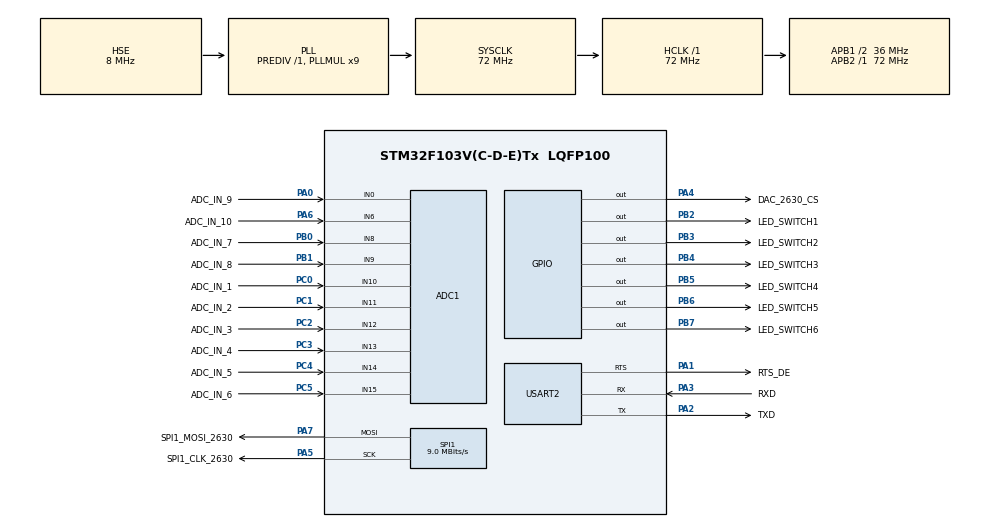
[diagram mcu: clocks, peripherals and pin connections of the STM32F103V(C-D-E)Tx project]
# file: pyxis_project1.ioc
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Mcu.Family=STM32F1
SPI1.VirtualType=VM_MASTER
ADC1.ContinuousConvMode=DISABLE
VP_TIM4_VS_OPM.Mode=OPM_bit
ADC1.SamplingTime-6\#ChannelRegularConversion=ADC_SAMPLETIME_71CYCLES_5
PC0.GPIO_Label=ADC_IN_1
PA6.GPIO_Label=ADC_IN_10
PB0.GPIO_Label=ADC_IN_7
PB6.GPIO_Label=LED_SWITCH5
ADC1.SamplingTime-12\#ChannelRegularConversion=ADC_SAMPLETIME_71CYCLES_5
ADC1.Channel-8\#ChannelRegularConversion=ADC_CHANNEL_15
RCC.SYSCLKSource=RCC_SYSCLKSOURCE_PLLCLK
ProjectManager.StackSize=0x400
ADC1.Channel-5\#ChannelRegularConversion=ADC_CHANNEL_12
ADC1.Rank-11\#ChannelRegularConversion=9
ADC1.Channel-3\#ChannelRegularConversion=ADC_CHANNEL_10
SPI1.Direction=SPI_DIRECTION_2LINES
RCC.HCLKFreq_Value=72000000
RCC.APB2TimFreq_Value=72000000
PB6.Signal=GPIO_Output
SPI1.CalculateBaudRate=9.0 MBits/s
PC3.Signal=ADCx_IN13
OSC_OUT.Mode=HSE-External-Oscillator
OSC_OUT.Signal=RCC_OSC_OUT
RCC.AHBFreq_Value=72000000
PB2.Signal=GPIO_Output
SH.ADCx_IN15.0=ADC1_IN15,IN15
RCC.PLLMUL=RCC_PLL_MUL9
ADC1.SamplingTime-4\#ChannelRegularConversion=ADC_SAMPLETIME_71CYCLES_5
ADC1.Channel-6\#ChannelRegularConversion=ADC_CHANNEL_13
PC14-OSC32_IN.Mode=LSE-External-Oscillator
PC4.GPIO_Label=ADC_IN_5
PA14.Mode=Serial_Wire
PB1.GPIO_Label=ADC_IN_8
SH.ADCx_IN8.0=ADC1_IN8,IN8
PB7.Signal=GPIO_Output
SH.ADCx_IN0.0=ADC1_IN0,IN0
TIM4.Period=49
PB7.GPIO_Label=LED_SWITCH6
Mcu.Package=LQFP100
ADC1.SamplingTime-11\#ChannelRegularConversion=ADC_SAMPLETIME_71CYCLES_5
PB1.Signal=ADCx_IN9
PA6.Signal=ADCx_IN6
SH.ADCx_IN14.0=ADC1_IN14,IN14
USART2.VirtualMode=VM_ASYNC
PA2.GPIO_Label=TXD
ADC1.Channel-11\#ChannelRegularConversion=ADC_CHANNEL_0
SH.ADCx_IN9.0=ADC1_IN9,IN9
PB5.GPIO_Label=LED_SWITCH4
RCC.APB1TimFreq_Value=72000000
PC5.Signal=ADCx_IN15
ADC1.Rank-6\#ChannelRegularConversion=4
SPI1.BaudRatePrescaler=SPI_BAUDRATEPRESCALER_8
ADC1.SamplingTime-8\#ChannelRegularConversion=ADC_SAMPLETIME_71CYCLES_5
PA4.GPIO_Label=DAC_2630_CS
PC2.GPIO_Label=ADC_IN_3
ADC1.Rank-4\#ChannelRegularConversion=2
PB4.Signal=GPIO_Output
PA3.Signal=USART2_RX
PA5.Mode=TX_Only_Simplex_Unidirect_Master
PB3.GPIO_Label=LED_SWITCH2
ADC1.Channel-10\#ChannelRegularConversion=ADC_CHANNEL_9
RCC.PLLSourceVirtual=RCC_PLLSOURCE_HSE
PC15-OSC32_OUT.Mode=LSE-External-Oscillator
SH.ADCx_IN13.0=ADC1_IN13,IN13
PA7.Mode=TX_Only_Simplex_Unidirect_Master
ADC1.Channel-4\#ChannelRegularConversion=ADC_CHANNEL_11
ADC1.Rank-10\#ChannelRegularConversion=8
SH.ADCx_IN6.0=ADC1_IN6,IN6
ADC1.Rank-8\#ChannelRegularConversion=6
PC2.Signal=ADCx_IN12
PC4.Signal=ADCx_IN14
ADC1.DiscontinuousConvMode=ENABLE
PC0.Signal=ADCx_IN10
RCC.APB1CLKDivider=RCC_HCLK_DIV2
PC14-OSC32_IN.Signal=RCC_OSC32_IN
NVIC.USART2_IRQn=true\:1\:0\:true\:false\:false\:true\:false
PA0-WKUP.GPIO_Label=ADC_IN_9
PA0-WKUP.Signal=ADCx_IN0
ADC1.Channel-7\#ChannelRegularConversion=ADC_CHANNEL_14
RCC.ADCPresc=RCC_ADCPCLK2_DIV6
PA3.Mode=Asynchronous
PA13.Signal=SYS_JTMS-SWDIO
SH.ADCx_IN12.0=ADC1_IN12,IN12
ProjectManager.TargetToolchain=MDK-ARM V5
OSC_IN.Signal=RCC_OSC_IN
RCC.USBFreq_Value=72000000
TIM4.Prescaler=7199
PC15-OSC32_OUT.Signal=RCC_OSC32_OUT
PA1.Signal=USART2_RTS
PA5.Signal=SPI1_SCK
board=custom
ADC1.Rank-12\#ChannelRegularConversion=10
ADC1.EnableAnalogWatchDog=false
ADC1.Channel-12\#ChannelRegularConversion=ADC_CHANNEL_6
RCC.APB2Freq_Value=72000000
PA1.Mode=RTS_Only
SH.ADCx_IN11.0=ADC1_IN11,IN11
PB4.GPIO_Label=LED_SWITCH3
SPI1.Mode=SPI_MODE_MASTER
PC1.GPIO_Label=ADC_IN_2
PA1.GPIO_Label=RTS_DE
ADC1.SamplingTime-10\#ChannelRegularConversion=ADC_SAMPLETIME_71CYCLES_5
ADC1.Rank-9\#ChannelRegularConversion=7
ADC1.NbrOfConversion=10
PA13.Mode=Serial_Wire
Mcu.Name=STM32F103V(C-D-E)Tx
PA2.Signal=USART2_TX
ADC1.Channel-9\#ChannelRegularConversion=ADC_CHANNEL_8
PB3.Signal=GPIO_Output
PA4.Signal=GPIO_Output
RCC.SYSCLKFreq_VALUE=72000000
PB5.Signal=GPIO_Output
PA7.GPIO_Label=SPI1_MOSI_2630
ADC1.master=1
PA5.GPIO_Label=SPI1_CLK_2630
ADC1.Rank-3\#ChannelRegularConversion=1
ADC1.SamplingTime-3\#ChannelRegularConversion=ADC_SAMPLETIME_71CYCLES_5
OSC_IN.Mode=HSE-External-Oscillator
PC5.GPIO_Label=ADC_IN_6
PA14.Signal=SYS_JTCK-SWCLK
SH.ADCx_IN10.0=ADC1_IN10,IN10
PB2.GPIO_Label=LED_SWITCH1
ProjectManager.HeapSize=0x200
ADC1.SamplingTime-5\#ChannelRegularConversion=ADC_SAMPLETIME_71CYCLES_5
ADC1.Rank-7\#ChannelRegularConversion=5
NVIC.PriorityGroup=NVIC_PRIORITYGROUP_4
ADC1.NbrOfConversionFlag=1
PA2.Mode=Asynchronous
PC3.GPIO_Label=ADC_IN_4
ADC1.SamplingTime-9\#ChannelRegularConversion=ADC_SAMPLETIME_71CYCLES_5
ADC1.SamplingTime-7\#ChannelRegularConversion=ADC_SAMPLETIME_71CYCLES_5
NVIC.TIM4_IRQn=true\:2\:0\:true\:false\:false\:true\:false
RCC.APB1Freq_Value=36000000
PB0.Signal=ADCx_IN8
ADC1.Rank-5\#ChannelRegularConversion=3
PC1.Signal=ADCx_IN11
PA3.GPIO_Label=RXD
PA7.Signal=SPI1_MOSI

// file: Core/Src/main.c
/* USER CODE BEGIN Header */
/**
  ******************************************************************************
  * @file           : main.c
  * @brief          : Main program body
  ******************************************************************************
  * @attention
  *
  * <h2><center>&copy; Copyright (c) 2020 STMicroelectronics.
  * All rights reserved.</center></h2>
  *
  * This software component is licensed by ST under BSD 3-Clause license,
  * the "License"; You may not use this file except in compliance with the
  * License. You may obtain a copy of the License at:
  *                        opensource.org/licenses/BSD-3-Clause
  *
  ******************************************************************************
  */
/* USER CODE END Header */

#include "main.h"
#include "adc.h"
#include "spi.h"
#include "tim.h"
#include "usart.h"
#include "gpio.h"

void SystemClock_Config(void);

/* USER CODE BEGIN 0 */
void vDelay(uint32_t ulTim)
{
	do
	{
		__NOP();
	}while(--ulTim);
}
/* USER CODE END 0 */

int main(void)
{
  /* USER CODE BEGIN 1 */
	uint8_t i;
	float avg_value[10];
  /* USER CODE END 1 */

  /* MCU Configuration--------------------------------------------------------*/

  /* Reset of all peripherals, Initializes the Flash interface and the Systick. */
  HAL_Init();

  /* USER CODE BEGIN Init */
	LTC2630ISC6_init();
	HAL_ADC_MspInit(&hadc1);
  /* USER CODE END Init */

  /* Configure the system clock */
  SystemClock_Config();

  /* Initialize all configured peripherals */
  MX_GPIO_Init();
  MX_ADC1_Init();
  MX_SPI1_Init();
  MX_USART2_UART_Init();
  MX_TIM4_Init();
  /* USER CODE BEGIN 2 */
//	HAL_SPI_MspInit(&hspi1);
  /* USER CODE END 2 */

  /* Infinite loop */
  /* USER CODE BEGIN WHILE */
	write_to_LTC2630ISC6(0x30,2000);
  while (1)
  {
    /* USER CODE END WHILE */

  }
}

void SystemClock_Config(void)
{
  RCC_OscInitTypeDef RCC_OscInitStruct = {0};
  RCC_ClkInitTypeDef RCC_ClkInitStruct = {0};
  RCC_PeriphCLKInitTypeDef PeriphClkInit = {0};

  /** Initializes the CPU, AHB and APB busses clocks
  */
  RCC_OscInitStruct.OscillatorType = RCC_OSCILLATORTYPE_HSE;
  RCC_OscInitStruct.HSEState = RCC_HSE_ON;
  RCC_OscInitStruct.HSEPredivValue = RCC_HSE_PREDIV_DIV1;
  RCC_OscInitStruct.HSIState = RCC_HSI_ON;
  RCC_OscInitStruct.PLL.PLLState = RCC_PLL_ON;
  RCC_OscInitStruct.PLL.PLLSource = RCC_PLLSOURCE_HSE;
  RCC_OscInitStruct.PLL.PLLMUL = RCC_PLL_MUL9;
  if (HAL_RCC_OscConfig(&RCC_OscInitStruct) != HAL_OK)
  {
    Error_Handler();
  }
  /** Initializes the CPU, AHB and APB busses clocks
  */
  RCC_ClkInitStruct.ClockType = RCC_CLOCKTYPE_HCLK|RCC_CLOCKTYPE_SYSCLK
                              |RCC_CLOCKTYPE_PCLK1|RCC_CLOCKTYPE_PCLK2;
  RCC_ClkInitStruct.SYSCLKSource = RCC_SYSCLKSOURCE_PLLCLK;
  RCC_ClkInitStruct.AHBCLKDivider = RCC_SYSCLK_DIV1;
  RCC_ClkInitStruct.APB1CLKDivider = RCC_HCLK_DIV2;
  RCC_ClkInitStruct.APB2CLKDivider = RCC_HCLK_DIV1;

  if (HAL_RCC_ClockConfig(&RCC_ClkInitStruct, FLASH_LATENCY_2) != HAL_OK)
  {
    Error_Handler();
  }
  PeriphClkInit.PeriphClockSelection = RCC_PERIPHCLK_ADC;
  PeriphClkInit.AdcClockSelection = RCC_ADCPCLK2_DIV6;
  if (HAL_RCCEx_PeriphCLKConfig(&PeriphClkInit) != HAL_OK)
  {
    Error_Handler();
  }
}

void Error_Handler(void)
{
}

/************************ (C) COPYRIGHT STMicroelectronics *****END OF FILE****/
